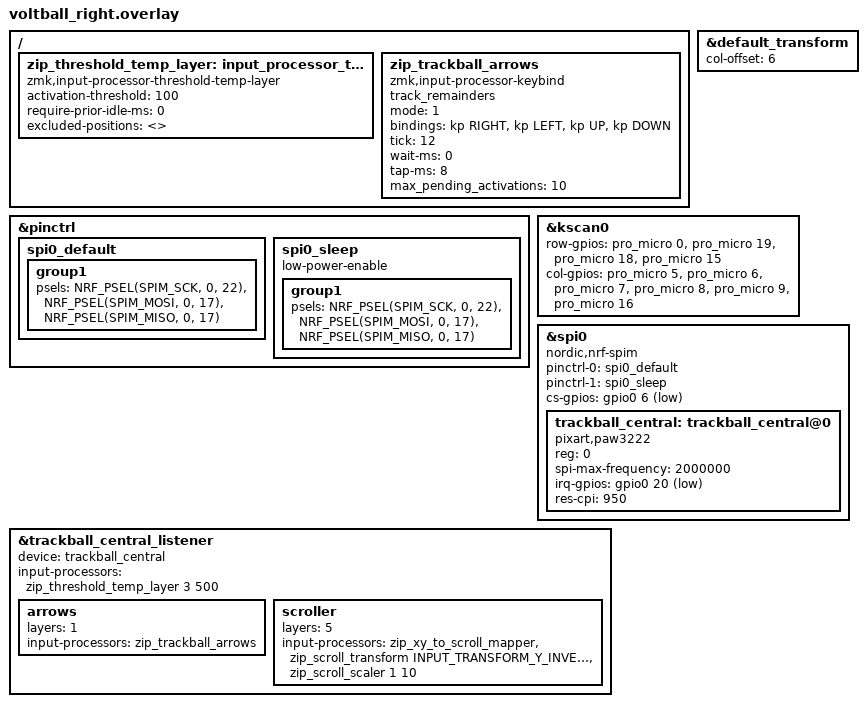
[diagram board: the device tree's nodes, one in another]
/*
 * SPDX-License-Identifier: MIT
 */

#include "voltball.dtsi"
#include <zephyr/dt-bindings/gpio/nordic-nrf-gpio.h>
#include <input/processors.dtsi>
#include <input/processors/zmk-input-processor-keybind.dtsi>
#include <zephyr/dt-bindings/input/input-event-codes.h>

/ {
    /*
     * 中文: 轨迹球移动超过阈值时临时进入指定层，用于把普通指针移动切到导航/鼠标层。
     * English: Temporarily activates a target layer when trackball movement exceeds the threshold.
     */
    zip_threshold_temp_layer: input_processor_threshold_temp_layer {
        compatible = "zmk,input-processor-threshold-temp-layer";
        #input-processor-cells = <2>;
        /* 中文: 指针移动累积到 100 后触发临时层；English: Activate after accumulated pointer motion reaches 100. */
        activation-threshold = <100>;
        /* 中文: 不要求触发前保持空闲；English: Do not require an idle period before activation. */
        require-prior-idle-ms = <0>;
        /* 中文: 不排除任何键位；English: No key positions are excluded from activation. */
        excluded-positions = <>;
    };

    /*
     * 中文: 第 1 层使用轨迹球输出四向方向键。
     * English: Converts trackball motion to four-way arrow keys on layer 1.
     */
    zip_trackball_arrows: zip_trackball_arrows {
        compatible = "zmk,input-processor-keybind";
        #input-processor-cells = <0>;
        track_remainders;
        mode = <1>;
        bindings = <&kp RIGHT>,
                   <&kp LEFT>,
                   <&kp UP>,
                   <&kp DOWN>;
        tick = <12>;
        wait-ms = <0>;
        tap-ms = <8>;
        max_pending_activations = <10>;
    };
};

&pinctrl {
    spi0_default: spi0_default {
        group1 {
            psels = <NRF_PSEL(SPIM_SCK, 0, 22)>,
                    <NRF_PSEL(SPIM_MOSI, 0, 17)>,
                    <NRF_PSEL(SPIM_MISO, 0, 17)>;
        };
    };

    spi0_sleep: spi0_sleep {
        group1 {
            psels = <NRF_PSEL(SPIM_SCK, 0, 22)>,
                    <NRF_PSEL(SPIM_MOSI, 0, 17)>,
                    <NRF_PSEL(SPIM_MISO, 0, 17)>;
        };
        low-power-enable;
    };
};

&default_transform {
    col-offset = <6>;
};

&kscan0 {
    row-gpios
        = <&pro_micro 0 (GPIO_ACTIVE_HIGH | GPIO_PULL_DOWN)>
        , <&pro_micro 19 (GPIO_ACTIVE_HIGH | GPIO_PULL_DOWN)>
        , <&pro_micro 18 (GPIO_ACTIVE_HIGH | GPIO_PULL_DOWN)>
        , <&pro_micro 15 (GPIO_ACTIVE_HIGH | GPIO_PULL_DOWN)>
        ;

    col-gpios
        = <&pro_micro 5 GPIO_ACTIVE_HIGH>
        , <&pro_micro 6 GPIO_ACTIVE_HIGH>
        , <&pro_micro 7 GPIO_ACTIVE_HIGH>
        , <&pro_micro 8 GPIO_ACTIVE_HIGH>
        , <&pro_micro 9 GPIO_ACTIVE_HIGH>
        , <&pro_micro 16 GPIO_ACTIVE_HIGH>
        ;
};

&spi0 {
    status = "okay";
    compatible = "nordic,nrf-spim";
    pinctrl-0 = <&spi0_default>;
    pinctrl-1 = <&spi0_sleep>;
    pinctrl-names = "default", "sleep";
    cs-gpios = <&gpio0 6 GPIO_ACTIVE_LOW>;

    trackball_central: trackball_central@0 {
        status = "okay";
        compatible = "pixart,paw3222";
        reg = <0>;
        spi-max-frequency = <2000000>;
        irq-gpios = <&gpio0 20 (GPIO_ACTIVE_LOW | GPIO_PULL_UP)>;
        /*
         * 中文: 驱动未配置 res-cpi 时会保留 PAW3222 传感器硬件默认值。
         * English: Without res-cpi, the driver keeps the PAW3222 sensor hardware default.
         *
         * 中文: 当前驱动有效范围是 608-4826 CPI，步进为 38；建议使用 38 的整数倍。
         * English: This driver accepts 608-4826 CPI in steps of 38; prefer multiples of 38.
         *
         * 中文: 常用值: 608, 760, 950, 1140, 1520, 1900, 2280, 2660, 3040, 3420, 3800, 4180, 4560, 4826。
         * English: Common values: 608, 760, 950, 1140, 1520, 1900, 2280, 2660, 3040, 3420, 3800, 4180, 4560, 4826.
         */
        res-cpi = <950>;
    };
};

&trackball_central_listener {
    status = "okay";
    device = <&trackball_central>;

    /*
     * 中文: 普通轨迹球模式。移动超过阈值后临时进入第 3 层 500ms。
     * English: Normal trackball mode activate layer 3 for 500 ms after threshold movement.
     */
    input-processors = <&zip_threshold_temp_layer 3 500>;

    /*
     * 中文: 第 1 层把轨迹球移动转换为上下左右方向键。
     * English: On layer 1, convert trackball motion to arrow-key taps.
     */
    arrows {
        layers = <1>;
        input-processors = <&zip_trackball_arrows>;
    };

    /*
     * 中文: 第 5 层启用滚动模式，把轨迹球移动转换成滚轮事件。
     * English: Layer 5 enables scroll mode, converting trackball movement into wheel events.
     */
    scroller {
        layers = <5>;
        input-processors =
            /* 中文: 将指针移动映射为滚动事件；English: Map pointer motion to scroll events. */
            <&zip_xy_to_scroll_mapper>,
            /* 中文: 反转滚动 Y 轴；English: Invert the scroll Y axis. */
            <&zip_scroll_transform INPUT_TRANSFORM_Y_INVERT>,
            /* 中文: 将滚动量缩放为 1/10；English: Scale scroll amount to 1/10. */
            <&zip_scroll_scaler 1 10>;
    };
};
